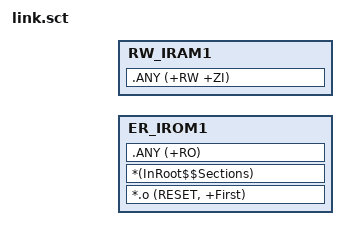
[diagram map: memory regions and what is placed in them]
#! armclang -E --target=arm-arm-none-eabi -mcpu=cortex-m33 -xc -I $SDK_ROOT/drivers/cmsis/sf32lb57x
#include "rtconfig.h"
#include "mem_map.h"


; *************************************************************
; *** Scatter-Loading Description File generated by uVision ***
; *************************************************************


LR_IROM1 CODE_START_ADDR CODE_SIZE  {    ; load region size_region
  ER_IROM1 CODE_START_ADDR CODE_SIZE  {  ; load address = execution address
   *.o (RESET, +First)
   *(InRoot$$Sections)
   .ANY (+RO)
  }
  RW_IRAM1 ACPU_RAM_DATA_START_ADDR ACPU_RAM_DATA_SIZE  {  ; RW data
   .ANY (+RW +ZI)
  }
}


;LR_IROM2 ACPU_CODE_REGION2_START_ADDR ACPU_CODE_REGION2_SIZE  {    ; load region size_region
;  ER_IROM2 ACPU_CODE_REGION2_START_ADDR ACPU_CODE_REGION2_SIZE  {  ; load address = execution address
;    *.o (.text.HAL_PMU_EnableXTAL32)
;  }
;}
